AUTOSAR XML (schema 3.1.2)
package /Components/SWC_ASE
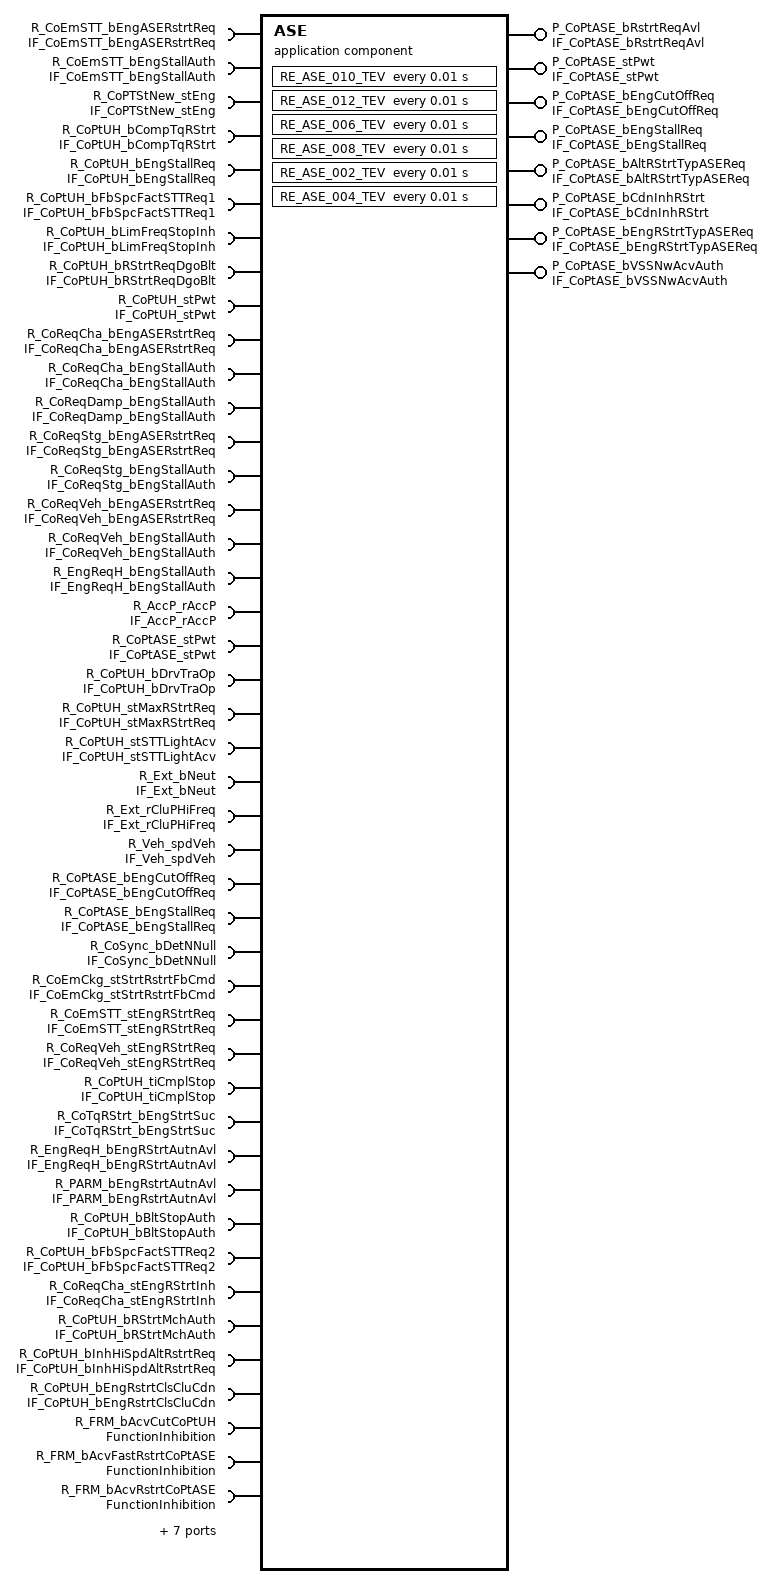
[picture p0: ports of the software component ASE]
  application software component type ASE
    49 x require port:
      R_CoEmSTT_bEngASERstrtReq: unqueued-receiver-com-spec{data-element=CoEmSTT_bEngASERstrtReq, init-value=CoEmSTT_bEngASERstrtReq_in, resync-time=0}, required-interface=IF_CoEmSTT_bEngASERstrtReq
      R_CoEmSTT_bEngStallAuth: unqueued-receiver-com-spec{data-element=CoEmSTT_bEngStallAuth, init-value=CoEmSTT_bEngStallAuth_in, resync-time=0}, required-interface=IF_CoEmSTT_bEngStallAuth
      R_CoPTStNew_stEng: unqueued-receiver-com-spec{data-element=CoPTStNew_stEng, init-value=CoPTStNew_stEng_in, resync-time=0}, required-interface=IF_CoPTStNew_stEng
      R_CoPtUH_bCompTqRStrt: unqueued-receiver-com-spec{data-element=CoPtUH_bCompTqRStrt, init-value=CoPtUH_bCompTqRStrt_in, resync-time=0}, required-interface=IF_CoPtUH_bCompTqRStrt
      R_CoPtUH_bEngStallReq: unqueued-receiver-com-spec{data-element=CoPtUH_bEngStallReq, init-value=CoPtUH_bEngStallReq_in, resync-time=0}, required-interface=IF_CoPtUH_bEngStallReq
      R_CoPtUH_bFbSpcFactSTTReq1: unqueued-receiver-com-spec{data-element=CoPtUH_bFbSpcFactSTTReq1, init-value=CoPtUH_bFbSpcFactSTTReq1_in, resync-time=0}, required-interface=IF_CoPtUH_bFbSpcFactSTTReq1
      R_CoPtUH_bLimFreqStopInh: unqueued-receiver-com-spec{data-element=CoPtUH_bLimFreqStopInh, init-value=CoPtUH_bLimFreqStopInh_in, resync-time=0}, required-interface=IF_CoPtUH_bLimFreqStopInh
      R_CoPtUH_bRStrtReqDgoBlt: unqueued-receiver-com-spec{data-element=CoPtUH_bRStrtReqDgoBlt, init-value=CoPtUH_bRStrtReqDgoBlt_in, resync-time=0}, required-interface=IF_CoPtUH_bRStrtReqDgoBlt
      R_CoPtUH_stPwt: unqueued-receiver-com-spec{data-element=CoPtUH_stPwt, init-value=CoPtUH_stPwt_in, resync-time=0}, required-interface=IF_CoPtUH_stPwt
      R_CoReqCha_bEngASERstrtReq: unqueued-receiver-com-spec{data-element=CoReqCha_bEngASERstrtReq, init-value=CoReqCha_bEngASERstrtReq_in, resync-time=0}, required-interface=IF_CoReqCha_bEngASERstrtReq
      R_CoReqCha_bEngStallAuth: unqueued-receiver-com-spec{data-element=CoReqCha_bEngStallAuth, init-value=CoReqCha_bEngStallAuth_in, resync-time=0}, required-interface=IF_CoReqCha_bEngStallAuth
      R_CoReqDamp_bEngStallAuth: unqueued-receiver-com-spec{data-element=CoReqDamp_bEngStallAuth, init-value=CoReqDamp_bEngStallAuth_in, resync-time=0}, required-interface=IF_CoReqDamp_bEngStallAuth
      R_CoReqStg_bEngASERstrtReq: unqueued-receiver-com-spec{data-element=CoReqStg_bEngASERstrtReq, init-value=CoReqStg_bEngASERstrtReq_in, resync-time=0}, required-interface=IF_CoReqStg_bEngASERstrtReq
      R_CoReqStg_bEngStallAuth: unqueued-receiver-com-spec{data-element=CoReqStg_bEngStallAuth, init-value=CoReqStg_bEngStallAuth_in, resync-time=0}, required-interface=IF_CoReqStg_bEngStallAuth
      R_CoReqVeh_bEngASERstrtReq: unqueued-receiver-com-spec{data-element=CoReqVeh_bEngASERstrtReq, init-value=CoReqVeh_bEngASERstrtReq_in, resync-time=0}, required-interface=IF_CoReqVeh_bEngASERstrtReq
      R_CoReqVeh_bEngStallAuth: unqueued-receiver-com-spec{data-element=CoReqVeh_bEngStallAuth, init-value=CoReqVeh_bEngStallAuth_in, resync-time=0}, required-interface=IF_CoReqVeh_bEngStallAuth
      R_EngReqH_bEngStallAuth: unqueued-receiver-com-spec{data-element=EngReqH_bEngStallAuth, init-value=EngReqH_bEngStallAuth_in, resync-time=0}, required-interface=IF_EngReqH_bEngStallAuth
      R_AccP_rAccP: unqueued-receiver-com-spec{data-element=AccP_rAccP, init-value=ConstantValue, resync-time=0}, required-interface=IF_AccP_rAccP
      R_CoPtASE_stPwt: unqueued-receiver-com-spec{data-element=CoPtASE_stPwt, init-value=CoPtASE_stPwt_in, resync-time=0}, required-interface=IF_CoPtASE_stPwt
      R_CoPtUH_bDrvTraOp: unqueued-receiver-com-spec{data-element=CoPtUH_bDrvTraOp, init-value=CoPtUH_bDrvTraOp_in, resync-time=0}, required-interface=IF_CoPtUH_bDrvTraOp
      R_CoPtUH_stMaxRStrtReq: unqueued-receiver-com-spec{data-element=CoPtUH_stMaxRStrtReq, init-value=CoPtUH_stMaxRStrtReq_in, resync-time=0}, required-interface=IF_CoPtUH_stMaxRStrtReq
      R_CoPtUH_stSTTLightAcv: unqueued-receiver-com-spec{data-element=CoPtUH_stSTTLightAcv, init-value=CoPtUH_stSTTLightAcv_in, resync-time=0}, required-interface=IF_CoPtUH_stSTTLightAcv
      R_Ext_bNeut: unqueued-receiver-com-spec{data-element=Ext_bNeut, init-value=Ext_bNeut_in, resync-time=0}, required-interface=IF_Ext_bNeut
      R_Ext_rCluPHiFreq: unqueued-receiver-com-spec{data-element=Ext_rCluPHiFreq, init-value=Ext_rCluPHiFreq_in, resync-time=0}, required-interface=IF_Ext_rCluPHiFreq
      R_Veh_spdVeh: unqueued-receiver-com-spec{data-element=Veh_spdVeh, init-value=ConstantValue1, resync-time=0}, required-interface=IF_Veh_spdVeh
      R_CoPtASE_bEngCutOffReq: unqueued-receiver-com-spec{data-element=CoPtASE_bEngCutOffReq, init-value=CoPtASE_bEngCutOffReq_in, resync-time=0}, required-interface=IF_CoPtASE_bEngCutOffReq
      R_CoPtASE_bEngStallReq: unqueued-receiver-com-spec{data-element=CoPtASE_bEngStallReq, init-value=CoPtASE_bEngStallReq_in, resync-time=0}, required-interface=IF_CoPtASE_bEngStallReq
      R_CoSync_bDetNNull: unqueued-receiver-com-spec{data-element=CoSync_bDetNNull, init-value=CoSync_bDetNNull_in, resync-time=0}, required-interface=IF_CoSync_bDetNNull
      R_CoEmCkg_stStrtRstrtFbCmd: unqueued-receiver-com-spec{data-element=CoEmCkg_stStrtRstrtFbCmd, init-value=CoEmCkg_stStrtRstrtFbCmd_in, resync-time=0}, required-interface=IF_CoEmCkg_stStrtRstrtFbCmd
      R_CoEmSTT_stEngRStrtReq: unqueued-receiver-com-spec{data-element=CoEmSTT_stEngRStrtReq, init-value=CoEmSTT_stEngRStrtReq_in, resync-time=0}, required-interface=IF_CoEmSTT_stEngRStrtReq
      R_CoReqVeh_stEngRStrtReq: unqueued-receiver-com-spec{data-element=CoReqVeh_stEngRStrtReq, init-value=CoReqVeh_stEngRStrtReq_in, resync-time=0}, required-interface=IF_CoReqVeh_stEngRStrtReq
      R_CoPtUH_tiCmplStop: unqueued-receiver-com-spec{data-element=CoPtUH_tiCmplStop, init-value=CoPtUH_tiCmplStop_in, resync-time=0}, required-interface=IF_CoPtUH_tiCmplStop
      R_CoTqRStrt_bEngStrtSuc: unqueued-receiver-com-spec{data-element=CoTqRStrt_bEngStrtSuc, init-value=CoTqRStrt_bEngStrtSuc_in, resync-time=0}, required-interface=IF_CoTqRStrt_bEngStrtSuc
      R_EngReqH_bEngRStrtAutnAvl: unqueued-receiver-com-spec{data-element=EngReqH_bEngRStrtAutnAvl, init-value=EngReqH_bEngRStrtAutnAvl_in, resync-time=0}, required-interface=IF_EngReqH_bEngRStrtAutnAvl
      R_PARM_bEngRstrtAutnAvl: unqueued-receiver-com-spec{data-element=PARM_bEngRstrtAutnAvl, init-value=PARM_bEngRstrtAutnAvl_in, resync-time=0}, required-interface=IF_PARM_bEngRstrtAutnAvl
      R_CoPtUH_bBltStopAuth: unqueued-receiver-com-spec{data-element=CoPtUH_bBltStopAuth, init-value=CoPtUH_bBltStopAuth_in, resync-time=0}, required-interface=IF_CoPtUH_bBltStopAuth
      R_CoPtUH_bFbSpcFactSTTReq2: unqueued-receiver-com-spec{data-element=CoPtUH_bFbSpcFactSTTReq2, init-value=CoPtUH_bFbSpcFactSTTReq2_in, resync-time=0}, required-interface=IF_CoPtUH_bFbSpcFactSTTReq2
      R_CoReqCha_stEngRStrtInh: unqueued-receiver-com-spec{data-element=CoReqCha_stEngRStrtInh, init-value=CoReqCha_stEngRStrtInh_in, resync-time=0}, required-interface=IF_CoReqCha_stEngRStrtInh
      R_CoPtUH_bRStrtMchAuth: unqueued-receiver-com-spec{data-element=CoPtUH_bRStrtMchAuth, init-value=CoPtUH_bRStrtMchAuth_in, resync-time=0}, required-interface=IF_CoPtUH_bRStrtMchAuth
      R_CoPtUH_bInhHiSpdAltRstrtReq: unqueued-receiver-com-spec{data-element=CoPtUH_bInhHiSpdAltRstrtReq, init-value=CoPtUH_bInhHiSpdAltRstrtReq_in, resync-time=0}, required-interface=IF_CoPtUH_bInhHiSpdAltRstrtReq
      R_CoPtUH_bEngRstrtClsCluCdn: unqueued-receiver-com-spec{data-element=CoPtUH_bEngRstrtClsCluCdn, init-value=CoPtUH_bEngRstrtClsCluCdn_in, resync-time=0}, required-interface=IF_CoPtUH_bEngRstrtClsCluCdn
      R_FRM_bAcvCutCoPtUH: required-interface=FunctionInhibition
      R_FRM_bAcvFastRstrtCoPtASE: required-interface=FunctionInhibition
      R_FRM_bAcvRstrtCoPtASE: required-interface=FunctionInhibition
      R_FRM_bInhCluPCoPtASE: required-interface=FunctionInhibition
      R_FRM_bInhNeutCoPtASE: required-interface=FunctionInhibition
      R_FRM_bInhSpdVehCoPtASE: required-interface=FunctionInhibition
      R_FRM_bAcvRunCoPtASE: required-interface=FunctionInhibition
      R_FRM_bAcvCutCoPtASE: required-interface=FunctionInhibition
    8 x provide port:
      P_CoPtASE_bRstrtReqAvl: unqueued-sender-com-spec{data-element=CoPtASE_bRstrtReqAvl, can-invalidate=false, init-value=CoPtASE_bRstrtReqAvl_out}, provided-interface=IF_CoPtASE_bRstrtReqAvl
      P_CoPtASE_stPwt: unqueued-sender-com-spec{data-element=CoPtASE_stPwt, can-invalidate=false, init-value=CoPtASE_stPwt_out}, provided-interface=IF_CoPtASE_stPwt
      P_CoPtASE_bEngCutOffReq: unqueued-sender-com-spec{data-element=CoPtASE_bEngCutOffReq, can-invalidate=false, init-value=CoPtASE_bEngCutOffReq_out}, provided-interface=IF_CoPtASE_bEngCutOffReq
      P_CoPtASE_bEngStallReq: unqueued-sender-com-spec{data-element=CoPtASE_bEngStallReq, can-invalidate=false, init-value=CoPtASE_bEngStallReq_out}, provided-interface=IF_CoPtASE_bEngStallReq
      P_CoPtASE_bAltRStrtTypASEReq: unqueued-sender-com-spec{data-element=CoPtASE_bAltRStrtTypASEReq, can-invalidate=false, init-value=CoPtASE_bAltRStrtTypASEReq_out}, provided-interface=IF_CoPtASE_bAltRStrtTypASEReq
      P_CoPtASE_bCdnInhRStrt: unqueued-sender-com-spec{data-element=CoPtASE_bCdnInhRStrt, can-invalidate=false, init-value=CoPtASE_bCdnInhRStrt_out}, provided-interface=IF_CoPtASE_bCdnInhRStrt
      P_CoPtASE_bEngRStrtTypASEReq: unqueued-sender-com-spec{data-element=CoPtASE_bEngRStrtTypASEReq, can-invalidate=false, init-value=CoPtASE_bEngRStrtTypASEReq_out}, provided-interface=IF_CoPtASE_bEngRStrtTypASEReq
      P_CoPtASE_bVSSNwAcvAuth: unqueued-sender-com-spec{data-element=CoPtASE_bVSSNwAcvAuth, can-invalidate=false, init-value=CoPtASE_bVSSNwAcvAuth_out}, provided-interface=IF_CoPtASE_bVSSNwAcvAuth
    require port R_UCE_stWkuMainRelSt: required-interface=IF_UCE_stWkuMainRelSt
    require port R_EcuM_CurrentMode: required-interface=EcuM_CurrentMode
  60 x constant specification:
    CoASE_bEngASEReqVld_Cst
      value:
        boolean literal CoASE_bEngASEReqVld_Cst: type=DT_CoASE_bEngASEReqVld, value=false
    CoASE_bHiSpdRstrtAuth_Cst
      value:
        boolean literal CoASE_bHiSpdRstrtAuth_Cst: type=DT_CoASE_bHiSpdRstrtAuth, value=false
    CoASE_spdVeh_Cst
      value:
        integer literal CoASE_spdVeh_Cst: type=DT_CoASE_spdVeh, value=0
    CoASE_stEngASEReqClas_Cst
      value:
        integer literal CoASE_stEngASEReqClas_Cst: type=DT_CoASE_stEngASEReqClas, value=0
    CoEmCkg_stStrtRstrtFbCmd_in
      value:
        integer literal CoEmCkg_stStrtRstrtFbCmd_in: type=DT_CoEmCkg_stStrtRstrtFbCmd, value=0
    CoEmSTT_bEngASERstrtReq_in
      value:
        boolean literal CoEmSTT_bEngASERstrtReq_in: type=DT_CoEmSTT_bEngASERstrtReq, value=false
    CoEmSTT_bEngStallAuth_in
      value:
        boolean literal CoEmSTT_bEngStallAuth_in: type=DT_CoEmSTT_bEngStallAuth, value=false
    CoEmSTT_stEngRStrtReq_in
      value:
        integer literal CoEmSTT_stEngRStrtReq_in: type=DT_CoEmSTT_stEngRStrtReq, value=0
    ConstantValue
      value:
        integer literal ConstantValue: type=DT_AccP_rAccP, value=0
    ConstantValue1
      value:
        integer literal ConstantValue1: type=DT_Veh_spdVeh, value=0
    CoPtASE_bAltRStrtTypASEReq_out
      value:
        boolean literal CoPtASE_bAltRStrtTypASEReq_out: type=DT_CoPtASE_bAltRStrtTypASEReq, value=false
    CoPtASE_bCdnInhRStrt_out
      value:
        boolean literal CoPtASE_bCdnInhRStrt_out: type=DT_CoPtASE_bCdnInhRStrt, value=true
    CoPtASE_bEngCutOffReq_in
      value:
        boolean literal CoPtASE_bEngCutOffReq_in: type=DT_CoPtASE_bEngCutOffReq, value=false
    CoPtASE_bEngCutOffReq_out
      value:
        boolean literal CoPtASE_bEngCutOffReq_out: type=DT_CoPtASE_bEngCutOffReq, value=false
    CoPtASE_bEngRStrtTypASEReq_out
      value:
        boolean literal CoPtASE_bEngRStrtTypASEReq_out: type=DT_CoPtASE_bEngRStrtTypASEReq, value=false
    CoPtASE_bEngStallReq_in
      value:
        boolean literal CoPtASE_bEngStallReq_in: type=DT_CoPtASE_bEngStallReq, value=false
    CoPtASE_bEngStallReq_out
      value:
        boolean literal CoPtASE_bEngStallReq_out: type=DT_CoPtASE_bEngStallReq, value=false
    CoPtASE_bRstrtReqAvl_out
      value:
        boolean literal CoPtASE_bRstrtReqAvl_out: type=DT_CoPtASE_bRstrtReqAvl, value=false
    CoPtASE_bVSSNwAcvAuth_out
      value:
        boolean literal CoPtASE_bVSSNwAcvAuth_out: type=DT_CoPtASE_bVSSNwAcvAuth, value=false
    CoPtASE_stPwt_in
      value:
        integer literal CoPtASE_stPwt_in: type=DT_CoPtASE_stPwt, value=1
    CoPtASE_stPwt_out
      value:
        integer literal CoPtASE_stPwt_out: type=DT_CoPtASE_stPwt, value=1
    CoPTStNew_stEng_in
      value:
        integer literal CoPTStNew_stEng_in: type=DT_CoPTStNew_stEng, value=1
    CoPtUH_bBltStopAuth_in
      value:
        boolean literal CoPtUH_bBltStopAuth_in: type=DT_CoPtUH_bBltStopAuth, value=false
    CoPtUH_bCompTqRStrt_in
      value:
        boolean literal CoPtUH_bCompTqRStrt_in: type=DT_CoPtUH_bCompTqRStrt, value=false
    CoPtUH_bDrvTraOp_in
      value:
        boolean literal CoPtUH_bDrvTraOp_in: type=DT_CoPtUH_bDrvTraOp, value=false
    CoPtUH_bEngRstrtClsCluCdn_in
      value:
        boolean literal CoPtUH_bEngRstrtClsCluCdn_in: type=DT_CoPtUH_bEngRstrtClsCluCdn, value=false
    CoPtUH_bEngStallReq_in
      value:
        boolean literal CoPtUH_bEngStallReq_in: type=DT_CoPtUH_bEngStallReq, value=false
    CoPtUH_bFbSpcFactSTTReq1_in
      value:
        boolean literal CoPtUH_bFbSpcFactSTTReq1_in: type=DT_CoPtUH_bFbSpcFactSTTReq1, value=false
    CoPtUH_bFbSpcFactSTTReq2_in
      value:
        boolean literal CoPtUH_bFbSpcFactSTTReq2_in: type=DT_CoPtUH_bFbSpcFactSTTReq2, value=false
    CoPtUH_bInhHiSpdAltRstrtReq_in
      value:
        boolean literal CoPtUH_bInhHiSpdAltRstrtReq_in: type=DT_CoPtUH_bInhHiSpdAltRstrtReq, value=false
    CoPtUH_bLimFreqStopInh_in
      value:
        boolean literal CoPtUH_bLimFreqStopInh_in: type=DT_CoPtUH_bLimFreqStopInh, value=false
    CoPtUH_bRStrtMchAuth_in
      value:
        boolean literal CoPtUH_bRStrtMchAuth_in: type=DT_CoPtUH_bRStrtMchAuth, value=false
    CoPtUH_bRStrtReqDgoBlt_in
      value:
        boolean literal CoPtUH_bRStrtReqDgoBlt_in: type=DT_CoPtUH_bRStrtReqDgoBlt, value=false
    CoPtUH_stMaxRStrtReq_in
      value:
        integer literal CoPtUH_stMaxRStrtReq_in: type=DT_CoPtUH_stMaxRStrtReq, value=0
    CoPtUH_stPwt_in
      value:
        integer literal CoPtUH_stPwt_in: type=DT_CoPtUH_stPwt, value=1
    CoPtUH_stSTTLightAcv_in
      value:
        integer literal CoPtUH_stSTTLightAcv_in: type=DT_CoPtUH_stSTTLightAcv, value=0
    CoPtUH_tiCmplStop_in
      value:
        integer literal CoPtUH_tiCmplStop_in: type=DT_CoPtUH_tiCmplStop, value=0
    CoReqCha_bEngASERstrtReq_in
      value:
        boolean literal CoReqCha_bEngASERstrtReq_in: type=DT_CoReqCha_bEngASERstrtReq, value=false
    CoReqCha_bEngStallAuth_in
      value:
        boolean literal CoReqCha_bEngStallAuth_in: type=DT_CoReqCha_bEngStallAuth, value=true
    CoReqCha_stEngRStrtInh_in
      value:
        integer literal CoReqCha_stEngRStrtInh_in: type=DT_CoReqCha_stEngRStrtInh, value=0
    CoReqDamp_bEngStallAuth_in
      value:
        boolean literal CoReqDamp_bEngStallAuth_in: type=DT_CoReqDamp_bEngStallAuth, value=true
    CoReqStg_bEngASERstrtReq_in
      value:
        boolean literal CoReqStg_bEngASERstrtReq_in: type=DT_CoReqStg_bEngASERstrtReq, value=false
    CoReqStg_bEngStallAuth_in
      value:
        boolean literal CoReqStg_bEngStallAuth_in: type=DT_CoReqStg_bEngStallAuth, value=true
    CoReqVeh_bEngASERstrtReq_in
      value:
        boolean literal CoReqVeh_bEngASERstrtReq_in: type=DT_CoReqVeh_bEngASERstrtReq, value=false
    CoReqVeh_bEngStallAuth_in
      value:
        boolean literal CoReqVeh_bEngStallAuth_in: type=DT_CoReqVeh_bEngStallAuth, value=true
    CoReqVeh_stEngRStrtReq_in
      value:
        integer literal CoReqVeh_stEngRStrtReq_in: type=DT_CoReqVeh_stEngRStrtReq, value=0
    CoStall_bEngStallAuth_Cst
      value:
        boolean literal CoStall_bEngStallAuth_Cst: type=DT_CoStall_bEngStallAuth, value=false
    CoStall_bEngStallReq_Cst
      value:
        boolean literal CoStall_bEngStallReq_Cst: type=DT_CoStall_bEngStallReq, value=false
    CoSync_bDetNNull_in
      value:
        boolean literal CoSync_bDetNNull_in: type=DT_CoSync_bDetNNull, value=false
    CoTqRStrt_bEngStrtSuc_in
      value:
        boolean literal CoTqRStrt_bEngStrtSuc_in: type=DT_CoTqRStrt_bEngStrtSuc, value=false
    EngReqH_bEngRStrtAutnAvl_in
      value:
        boolean literal EngReqH_bEngRStrtAutnAvl_in: type=DT_EngReqH_bEngRStrtAutnAvl, value=false
    EngReqH_bEngStallAuth_in
      value:
        boolean literal EngReqH_bEngStallAuth_in: type=DT_EngReqH_bEngStallAuth, value=true
    Ext_bNeut_in
      value:
        boolean literal Ext_bNeut_in: type=DT_Ext_bNeut, value=false
    Ext_rCluPHiFreq_in
      value:
        integer literal Ext_rCluPHiFreq_in: type=DT_Ext_rCluPHiFreq, value=0
    MgtASECut_bRstrtMchInh_Cst
      value:
        boolean literal MgtASECut_bRstrtMchInh_Cst: type=DT_MgtASECut_bRstrtMchInh, value=true
    MgtStall_bEngASEEndTi_Cst
      value:
        boolean literal MgtStall_bEngASEEndTi_Cst: type=DT_MgtStall_bEngASEEndTi, value=false
    MgtStall_bMissRstrtTmp_Cst
      value:
        boolean literal MgtStall_bMissRstrtTmp_Cst: type=DT_MgtStall_bMissRstrtTmp, value=false
    MgtStall_bStallAuthNbASE_Cst
      value:
        boolean literal MgtStall_bStallAuthNbASE_Cst: type=DT_MgtStall_bStallAuthNbASE, value=false
    MgtStall_bStallAuthNbRstrt_Cst
      value:
        boolean literal MgtStall_bStallAuthNbRstrt_Cst: type=DT_MgtStall_bStallAuthNbRstrt, value=false
    PARM_bEngRstrtAutnAvl_in
      value:
        boolean literal PARM_bEngRstrtAutnAvl_in: type=DT_PARM_bEngRstrtAutnAvl, value=false
  internal behavior IB_ASE: component=ASE
    mode switch event EV_ASE_003_MSE: start-on-event=RE_ASE_003_MSE, activation=ENTRY, mode=R_EcuM_CurrentMode.currentMode.RUN
    timing event EV_ASE_010_TEV: mode-dependency=dependent-on-mode=[R_UCE_stWkuMainRelSt.RCD_stWkuMainRelSt.PreMainWakeUp, R_UCE_stWkuMainRelSt.RCD_stWkuMainRelSt.PostMainWakeUp, R_UCE_stWkuMainRelSt.RCD_stWkuMainRelSt.Invalid], start-on-event=RE_ASE_010_TEV, period=0.01
    timing event EV_ASE_012_TEV: mode-dependency=dependent-on-mode=[R_UCE_stWkuMainRelSt.RCD_stWkuMainRelSt.PreMainWakeUp, R_UCE_stWkuMainRelSt.RCD_stWkuMainRelSt.PostMainWakeUp, R_UCE_stWkuMainRelSt.RCD_stWkuMainRelSt.Invalid], start-on-event=RE_ASE_012_TEV, period=0.01
    mode switch event EV_ASE_005_MSE: start-on-event=RE_ASE_005_MSE, activation=ENTRY, mode=R_EcuM_CurrentMode.currentMode.RUN
    timing event EV_ASE_006_TEV: mode-dependency=dependent-on-mode=[R_UCE_stWkuMainRelSt.RCD_stWkuMainRelSt.PreMainWakeUp, R_UCE_stWkuMainRelSt.RCD_stWkuMainRelSt.PostMainWakeUp, R_UCE_stWkuMainRelSt.RCD_stWkuMainRelSt.Invalid], start-on-event=RE_ASE_006_TEV, period=0.01
    mode switch event EV_ASE_001_MSE: start-on-event=RE_ASE_001_MSE, activation=ENTRY, mode=R_EcuM_CurrentMode.currentMode.RUN
    mode switch event EV_ASE_009_MSE: start-on-event=RE_ASE_009_MSE, activation=ENTRY, mode=R_EcuM_CurrentMode.currentMode.RUN
    mode switch event EV_ASE_011_MSE: start-on-event=RE_ASE_011_MSE, activation=ENTRY, mode=R_EcuM_CurrentMode.currentMode.RUN
    timing event EV_ASE_008_TEV: mode-dependency=dependent-on-mode=[R_UCE_stWkuMainRelSt.RCD_stWkuMainRelSt.PreMainWakeUp, R_UCE_stWkuMainRelSt.RCD_stWkuMainRelSt.PostMainWakeUp, R_UCE_stWkuMainRelSt.RCD_stWkuMainRelSt.Invalid], start-on-event=RE_ASE_008_TEV, period=0.01
    timing event EV_ASE_002_TEV: mode-dependency=dependent-on-mode=[R_UCE_stWkuMainRelSt.RCD_stWkuMainRelSt.PreMainWakeUp, R_UCE_stWkuMainRelSt.RCD_stWkuMainRelSt.PostMainWakeUp, R_UCE_stWkuMainRelSt.RCD_stWkuMainRelSt.Invalid], start-on-event=RE_ASE_002_TEV, period=0.01
    mode switch event EV_ASE_007_MSE: start-on-event=RE_ASE_007_MSE, activation=ENTRY, mode=R_EcuM_CurrentMode.currentMode.RUN
    timing event EV_ASE_004_TEV: mode-dependency=dependent-on-mode=[R_UCE_stWkuMainRelSt.RCD_stWkuMainRelSt.PreMainWakeUp, R_UCE_stWkuMainRelSt.RCD_stWkuMainRelSt.PostMainWakeUp, R_UCE_stWkuMainRelSt.RCD_stWkuMainRelSt.Invalid], start-on-event=RE_ASE_004_TEV, period=0.01
    11 x inter runnable variable, all with sw-calibration-access=READ-WRITE, communication-approach=EXPLICIT:
      CoASE_bEngASEReqVld: type=DT_CoASE_bEngASEReqVld, init-value=CoASE_bEngASEReqVld_Cst
      MgtStall_bStallAuthNbASE: type=DT_MgtStall_bStallAuthNbASE, init-value=MgtStall_bStallAuthNbASE_Cst
      CoStall_bEngStallReq: type=DT_CoStall_bEngStallReq, init-value=CoStall_bEngStallReq_Cst
      MgtASECut_bRstrtMchInh: type=DT_MgtASECut_bRstrtMchInh, init-value=MgtASECut_bRstrtMchInh_Cst
      CoASE_bHiSpdRstrtAuth: type=DT_CoASE_bHiSpdRstrtAuth, init-value=CoASE_bHiSpdRstrtAuth_Cst
      CoASE_stEngASEReqClas: type=DT_CoASE_stEngASEReqClas, init-value=CoASE_stEngASEReqClas_Cst
      CoASE_spdVeh: type=DT_CoASE_spdVeh, init-value=CoASE_spdVeh_Cst
      CoStall_bEngStallAuth: type=DT_CoStall_bEngStallAuth, init-value=CoStall_bEngStallAuth_Cst
      MgtStall_bEngASEEndTi: type=DT_MgtStall_bEngASEEndTi, init-value=MgtStall_bEngASEEndTi_Cst
      MgtStall_bStallAuthNbRstrt: type=DT_MgtStall_bStallAuthNbRstrt, init-value=MgtStall_bStallAuthNbRstrt_Cst
      MgtStall_bMissRstrtTmp: type=DT_MgtStall_bMissRstrtTmp, init-value=MgtStall_bMissRstrtTmp_Cst
    12 x runnable:
      RE_ASE_002_TEV: read-variable=[MgtStall_bStallAuthNbRstrt, CoASE_stEngASEReqClas, MgtStall_bStallAuthNbASE, CoASE_spdVeh], written-variable=[CoStall_bEngStallAuth, CoStall_bEngStallReq]
        19 x data receive point:
          dr_CoReqStg_bEngStallAuth: data-element=R_CoReqStg_bEngStallAuth.CoReqStg_bEngStallAuth
          dr_CoReqStg_bEngASERstrtReq: data-element=R_CoReqStg_bEngASERstrtReq.CoReqStg_bEngASERstrtReq
          dr_CoPtUH_bBltStopAuth: data-element=R_CoPtUH_bBltStopAuth.CoPtUH_bBltStopAuth
          dr_CoReqVeh_bEngStallAuth: data-element=R_CoReqVeh_bEngStallAuth.CoReqVeh_bEngStallAuth
          dr_CoEmSTT_bEngStallAuth: data-element=R_CoEmSTT_bEngStallAuth.CoEmSTT_bEngStallAuth
          dr_CoReqCha_bEngASERstrtReq: data-element=R_CoReqCha_bEngASERstrtReq.CoReqCha_bEngASERstrtReq
          dr_CoEmSTT_bEngASERstrtReq: data-element=R_CoEmSTT_bEngASERstrtReq.CoEmSTT_bEngASERstrtReq
          dr_CoPtUH_bFbSpcFactSTTReq2: data-element=R_CoPtUH_bFbSpcFactSTTReq2.CoPtUH_bFbSpcFactSTTReq2
          dr_CoPtUH_bFbSpcFactSTTReq1: data-element=R_CoPtUH_bFbSpcFactSTTReq1.CoPtUH_bFbSpcFactSTTReq1
          dr_CoReqCha_bEngStallAuth: data-element=R_CoReqCha_bEngStallAuth.CoReqCha_bEngStallAuth
          dr_CoReqVeh_bEngASERstrtReq: data-element=R_CoReqVeh_bEngASERstrtReq.CoReqVeh_bEngASERstrtReq
          dr_CoPtUH_bLimFreqStopInh: data-element=R_CoPtUH_bLimFreqStopInh.CoPtUH_bLimFreqStopInh
          dr_CoReqDamp_bEngStallAuth: data-element=R_CoReqDamp_bEngStallAuth.CoReqDamp_bEngStallAuth
          dr_CoPtUH_bEngStallReq: data-element=R_CoPtUH_bEngStallReq.CoPtUH_bEngStallReq
          dr_CoPtUH_bCompTqRStrt: data-element=R_CoPtUH_bCompTqRStrt.CoPtUH_bCompTqRStrt
          dr_CoPTStNew_stEng: data-element=R_CoPTStNew_stEng.CoPTStNew_stEng
          dr_EngReqH_bEngStallAuth: data-element=R_EngReqH_bEngStallAuth.EngReqH_bEngStallAuth
          dr_CoPtUH_stPwt: data-element=R_CoPtUH_stPwt.CoPtUH_stPwt
          dr_CoPtUH_bRStrtReqDgoBlt: data-element=R_CoPtUH_bRStrtReqDgoBlt.CoPtUH_bRStrtReqDgoBlt
        sync call ssp_FRM_bAcvFastRstrtCoPtASE: operation=R_FRM_bAcvFastRstrtCoPtASE.GetFunctionPermission
        sync call ssp_FRM_bAcvCutCoPtASE: operation=R_FRM_bAcvCutCoPtASE.GetFunctionPermission
        sync call ssp_FRM_bAcvRstrtCoPtASE: operation=R_FRM_bAcvRstrtCoPtASE.GetFunctionPermission
      RE_ASE_011_MSE
        4 x data send point:
          ds_CoPtASE_bAltRStrtTypASEReq: data-element=P_CoPtASE_bAltRStrtTypASEReq.CoPtASE_bAltRStrtTypASEReq
          ds_CoPtASE_bEngRStrtTypASEReq: data-element=P_CoPtASE_bEngRStrtTypASEReq.CoPtASE_bEngRStrtTypASEReq
          ds_CoPtASE_bCdnInhRStrt: data-element=P_CoPtASE_bCdnInhRStrt.CoPtASE_bCdnInhRStrt
          ds_CoPtASE_bVSSNwAcvAuth: data-element=P_CoPtASE_bVSSNwAcvAuth.CoPtASE_bVSSNwAcvAuth
      RE_ASE_005_MSE
        data send point ds_CoPtASE_stPwt: data-element=P_CoPtASE_stPwt.CoPtASE_stPwt
      RE_ASE_012_TEV: read-variable=CoASE_bHiSpdRstrtAuth
        8 x data receive point:
          dr_CoTqRStrt_bEngStrtSuc: data-element=R_CoTqRStrt_bEngStrtSuc.CoTqRStrt_bEngStrtSuc
          dr_EngReqH_bEngRStrtAutnAvl: data-element=R_EngReqH_bEngRStrtAutnAvl.EngReqH_bEngRStrtAutnAvl
          dr_CoEmCkg_stStrtRstrtFbCmd: data-element=R_CoEmCkg_stStrtRstrtFbCmd.CoEmCkg_stStrtRstrtFbCmd
          dr_CoPtASE_bEngStallReq: data-element=R_CoPtASE_bEngStallReq.CoPtASE_bEngStallReq
          dr_CoPtUH_bEngRstrtClsCluCdn: data-element=R_CoPtUH_bEngRstrtClsCluCdn.CoPtUH_bEngRstrtClsCluCdn
          dr_CoPtASE_stPwt: data-element=R_CoPtASE_stPwt.CoPtASE_stPwt
          dr_PARM_bEngRstrtAutnAvl: data-element=R_PARM_bEngRstrtAutnAvl.PARM_bEngRstrtAutnAvl
          dr_CoPtASE_bEngCutOffReq: data-element=R_CoPtASE_bEngCutOffReq.CoPtASE_bEngCutOffReq
        4 x data send point:
          ds_CoPtASE_bAltRStrtTypASEReq: data-element=P_CoPtASE_bAltRStrtTypASEReq.CoPtASE_bAltRStrtTypASEReq
          ds_CoPtASE_bVSSNwAcvAuth: data-element=P_CoPtASE_bVSSNwAcvAuth.CoPtASE_bVSSNwAcvAuth
          ds_CoPtASE_bEngRStrtTypASEReq: data-element=P_CoPtASE_bEngRStrtTypASEReq.CoPtASE_bEngRStrtTypASEReq
          ds_CoPtASE_bCdnInhRStrt: data-element=P_CoPtASE_bCdnInhRStrt.CoPtASE_bCdnInhRStrt
      RE_ASE_006_TEV: read-variable=[MgtStall_bEngASEEndTi, CoASE_bEngASEReqVld, CoStall_bEngStallAuth, CoStall_bEngStallReq]
        4 x data receive point:
          dr_CoPtASE_bEngStallReq: data-element=R_CoPtASE_bEngStallReq.CoPtASE_bEngStallReq
          dr_CoPtASE_bEngCutOffReq: data-element=R_CoPtASE_bEngCutOffReq.CoPtASE_bEngCutOffReq
          dr_CoSync_bDetNNull: data-element=R_CoSync_bDetNNull.CoSync_bDetNNull
          dr_CoPTStNew_stEng: data-element=R_CoPTStNew_stEng.CoPTStNew_stEng
        data send point ds_CoPtASE_stPwt: data-element=P_CoPtASE_stPwt.CoPtASE_stPwt
        sync call ssp_FRM_bAcvRunCoPtASE: operation=R_FRM_bAcvRunCoPtASE.GetFunctionPermission
      RE_ASE_004_TEV: written-variable=[CoASE_bEngASEReqVld, CoASE_spdVeh, CoASE_bHiSpdRstrtAuth, CoASE_stEngASEReqClas]
        16 x data receive point:
          dr_CoPtUH_stSTTLightAcv: data-element=R_CoPtUH_stSTTLightAcv.CoPtUH_stSTTLightAcv
          dr_Veh_spdVeh: data-element=R_Veh_spdVeh.Veh_spdVeh
          dr_CoPtASE_stPwt: data-element=R_CoPtASE_stPwt.CoPtASE_stPwt
          dr_CoReqVeh_bEngASERstrtReq: data-element=R_CoReqVeh_bEngASERstrtReq.CoReqVeh_bEngASERstrtReq
          dr_CoPtUH_stMaxRStrtReq: data-element=R_CoPtUH_stMaxRStrtReq.CoPtUH_stMaxRStrtReq
          dr_CoEmSTT_bEngASERstrtReq: data-element=R_CoEmSTT_bEngASERstrtReq.CoEmSTT_bEngASERstrtReq
          dr_CoPtUH_bDrvTraOp: data-element=R_CoPtUH_bDrvTraOp.CoPtUH_bDrvTraOp
          dr_Ext_rCluPHiFreq: data-element=R_Ext_rCluPHiFreq.Ext_rCluPHiFreq
          dr_CoPtUH_bInhHiSpdAltRstrtReq: data-element=R_CoPtUH_bInhHiSpdAltRstrtReq.CoPtUH_bInhHiSpdAltRstrtReq
          dr_CoReqCha_stEngRStrtInh: data-element=R_CoReqCha_stEngRStrtInh.CoReqCha_stEngRStrtInh
          dr_CoReqCha_bEngASERstrtReq: data-element=R_CoReqCha_bEngASERstrtReq.CoReqCha_bEngASERstrtReq
          dr_CoPtUH_bCompTqRStrt: data-element=R_CoPtUH_bCompTqRStrt.CoPtUH_bCompTqRStrt
          dr_Ext_bNeut: data-element=R_Ext_bNeut.Ext_bNeut
          dr_CoReqStg_bEngASERstrtReq: data-element=R_CoReqStg_bEngASERstrtReq.CoReqStg_bEngASERstrtReq
          dr_CoPtUH_bRStrtReqDgoBlt: data-element=R_CoPtUH_bRStrtReqDgoBlt.CoPtUH_bRStrtReqDgoBlt
          dr_AccP_rAccP: data-element=R_AccP_rAccP.AccP_rAccP
        data send point ds_CoPtASE_bRstrtReqAvl: data-element=P_CoPtASE_bRstrtReqAvl.CoPtASE_bRstrtReqAvl
        5 x sync call:
          ssp_FRM_bInhNeutCoPtASE: operation=R_FRM_bInhNeutCoPtASE.GetFunctionPermission
          ssp_FRM_bInhCluPCoPtASE: operation=R_FRM_bInhCluPCoPtASE.GetFunctionPermission
          ssp_FRM_bAcvFastRstrtCoPtASE: operation=R_FRM_bAcvFastRstrtCoPtASE.GetFunctionPermission
          ssp_FRM_bAcvRstrtCoPtASE: operation=R_FRM_bAcvRstrtCoPtASE.GetFunctionPermission
          ssp_FRM_bInhSpdVehCoPtASE: operation=R_FRM_bInhSpdVehCoPtASE.GetFunctionPermission
      RE_ASE_008_TEV: read-variable=[MgtStall_bStallAuthNbASE, CoStall_bEngStallAuth, CoASE_stEngASEReqClas, MgtStall_bMissRstrtTmp, CoASE_spdVeh, CoStall_bEngStallReq, MgtStall_bStallAuthNbRstrt], written-variable=MgtASECut_bRstrtMchInh
        7 x data receive point:
          dr_CoEmSTT_stEngRStrtReq: data-element=R_CoEmSTT_stEngRStrtReq.CoEmSTT_stEngRStrtReq
          dr_CoPtASE_stPwt: data-element=R_CoPtASE_stPwt.CoPtASE_stPwt
          dr_CoEmCkg_stStrtRstrtFbCmd: data-element=R_CoEmCkg_stStrtRstrtFbCmd.CoEmCkg_stStrtRstrtFbCmd
          dr_CoReqVeh_stEngRStrtReq: data-element=R_CoReqVeh_stEngRStrtReq.CoReqVeh_stEngRStrtReq
          dr_CoPtUH_bDrvTraOp: data-element=R_CoPtUH_bDrvTraOp.CoPtUH_bDrvTraOp
          dr_CoPtUH_bRStrtMchAuth: data-element=R_CoPtUH_bRStrtMchAuth.CoPtUH_bRStrtMchAuth
          dr_CoReqCha_stEngRStrtInh: data-element=R_CoReqCha_stEngRStrtInh.CoReqCha_stEngRStrtInh
        data send point ds_CoPtASE_bEngCutOffReq: data-element=P_CoPtASE_bEngCutOffReq.CoPtASE_bEngCutOffReq
        sync call ssp_FRM_bAcvCutCoPtASE: operation=R_FRM_bAcvCutCoPtASE.GetFunctionPermission
        sync call ssp_FRM_bAcvCutCoPtUH: operation=R_FRM_bAcvCutCoPtUH.GetFunctionPermission
      RE_ASE_007_MSE: written-variable=MgtASECut_bRstrtMchInh
        data send point ds_CoPtASE_bEngCutOffReq: data-element=P_CoPtASE_bEngCutOffReq.CoPtASE_bEngCutOffReq
      RE_ASE_010_TEV: read-variable=MgtASECut_bRstrtMchInh, written-variable=[MgtStall_bMissRstrtTmp, MgtStall_bStallAuthNbRstrt, MgtStall_bStallAuthNbASE, MgtStall_bEngASEEndTi]
        6 x data receive point:
          dr_CoEmCkg_stStrtRstrtFbCmd: data-element=R_CoEmCkg_stStrtRstrtFbCmd.CoEmCkg_stStrtRstrtFbCmd
          dr_CoPtUH_tiCmplStop: data-element=R_CoPtUH_tiCmplStop.CoPtUH_tiCmplStop
          dr_CoPtASE_bEngCutOffReq: data-element=R_CoPtASE_bEngCutOffReq.CoPtASE_bEngCutOffReq
          dr_CoPtASE_stPwt: data-element=R_CoPtASE_stPwt.CoPtASE_stPwt
          dr_CoReqCha_stEngRStrtInh: data-element=R_CoReqCha_stEngRStrtInh.CoReqCha_stEngRStrtInh
          dr_CoPtUH_stPwt: data-element=R_CoPtUH_stPwt.CoPtUH_stPwt
        data send point ds_CoPtASE_bEngStallReq: data-element=P_CoPtASE_bEngStallReq.CoPtASE_bEngStallReq
      RE_ASE_003_MSE: written-variable=[CoASE_bEngASEReqVld, CoASE_stEngASEReqClas, CoASE_bHiSpdRstrtAuth, CoASE_spdVeh]
        data send point ds_CoPtASE_bRstrtReqAvl: data-element=P_CoPtASE_bRstrtReqAvl.CoPtASE_bRstrtReqAvl
      RE_ASE_009_MSE: written-variable=[MgtStall_bStallAuthNbASE, MgtStall_bStallAuthNbRstrt, MgtStall_bMissRstrtTmp, MgtStall_bEngASEEndTi]
        data send point ds_CoPtASE_bEngStallReq: data-element=P_CoPtASE_bEngStallReq.CoPtASE_bEngStallReq
      RE_ASE_001_MSE: written-variable=[CoStall_bEngStallReq, CoStall_bEngStallAuth]
  swc implementation Imp_ASE: programming-language=C, behavior=IB_ASE
    code-descriptors:
      code CodeDescriptor: type=SRC
        27 x xfile:
          ASE_MemMap_h: url=ASE_MemMap.h
          ASE_006_TEV_fct_h: url=ASE_006_TEV_fct.h
          ASE_004_TEV_fct_h: url=ASE_004_TEV_fct.h
          ASE_012_TEV_fct_h: url=ASE_012_TEV_fct.h
          ASE_c: url=ASE.c
          ASE_012_calibrations_c: url=ASE_012_calibrations.c
          ASE_008_TEV_fct_c: url=ASE_008_TEV_fct.c
          ASE_010_calibrations_h: url=ASE_010_calibrations.h
          ASE_006_TEV_fct_c: url=ASE_006_TEV_fct.c
          ASE_002_TEV_fct_c: url=ASE_002_TEV_fct.c
          ASE_006_calibrations_h: url=ASE_006_calibrations.h
          ASE_006_calibrations_c: url=ASE_006_calibrations.c
          ASE_004_TEV_fct_c: url=ASE_004_TEV_fct.c
          ASE_004_calibrations_h: url=ASE_004_calibrations.h
          ASE_010_TEV_fct_h: url=ASE_010_TEV_fct.h
          ASE_002_TEV_fct_h: url=ASE_002_TEV_fct.h
          ASE_010_calibrations_c: url=ASE_010_calibrations.c
          ASE_010_TEV_fct_c: url=ASE_010_TEV_fct.c
          ASE_008_calibrations_h: url=ASE_008_calibrations.h
          ASE_002_calibrations_h: url=ASE_002_calibrations.h
          ASE_008_calibrations_c: url=ASE_008_calibrations.c
          ASE_h: url=ASE.h
          ASE_008_TEV_fct_h: url=ASE_008_TEV_fct.h
          ASE_012_calibrations_h: url=ASE_012_calibrations.h
          ASE_012_TEV_fct_c: url=ASE_012_TEV_fct.c
          ASE_004_calibrations_c: url=ASE_004_calibrations.c
          ASE_002_calibrations_c: url=ASE_002_calibrations.c
package /Components/SWC_ASE/ASE_IRVDatatypes
  9 x boolean type, all with base-type=boolean:
    DT_CoASE_bEngASEReqVld
    DT_CoASE_bHiSpdRstrtAuth
    DT_CoStall_bEngStallAuth
    DT_CoStall_bEngStallReq
    DT_MgtASECut_bRstrtMchInh
    DT_MgtStall_bEngASEEndTi
    DT_MgtStall_bMissRstrtTmp
    DT_MgtStall_bStallAuthNbASE
    DT_MgtStall_bStallAuthNbRstrt
  integer type DT_CoASE_spdVeh: base-type=uint16, lower-limit=0, upper-limit=65535
  integer type DT_CoASE_stEngASEReqClas: base-type=uint8, lower-limit=0, upper-limit=255
